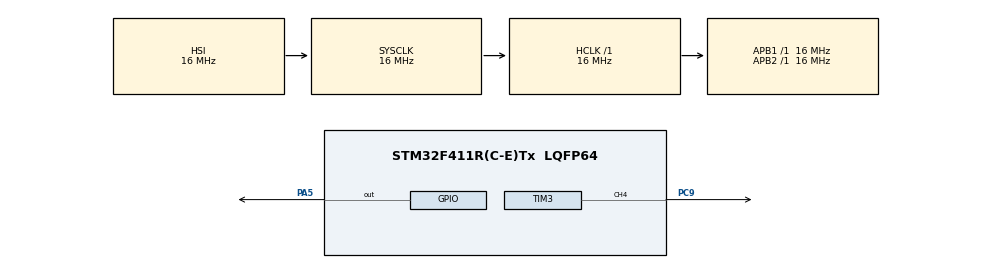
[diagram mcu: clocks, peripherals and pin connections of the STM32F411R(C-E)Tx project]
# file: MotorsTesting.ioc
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Mcu.Family=STM32F4
Mcu.Name=STM32F411R(C-E)Tx
Mcu.Package=LQFP64
NVIC.PriorityGroup=NVIC_PRIORITYGROUP_4
PA5.Signal=GPIO_Output
PC9.Signal=S_TIM3_CH4
ProjectManager.HeapSize=0x200
ProjectManager.StackSize=0x400
ProjectManager.TargetToolchain=STM32CubeIDE
RCC.AHBFreq_Value=16000000
RCC.APB1Freq_Value=16000000
RCC.APB2Freq_Value=16000000
RCC.CortexFreq_Value=16000000
RCC.HSE_VALUE=25000000
RCC.HSI_VALUE=16000000
RCC.LSE_VALUE=32768
RCC.SYSCLKFreq_VALUE=16000000
RCC.VCOOutputFreq_Value=192000000
SH.S_TIM3_CH4.0=TIM3_CH4,PWM Generation4 CH4
TIM3.Channel-PWM\ Generation4\ CH4=TIM_CHANNEL_4
TIM3.Period=15999
TIM3.Prescaler=999
TIM3.Pulse-PWM\ Generation4\ CH4=32000
board=custom

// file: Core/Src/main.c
/* USER CODE BEGIN Header */
/* USER CODE END Header */
#include "main.h"

TIM_HandleTypeDef htim3;

void SystemClock_Config(void);
static void MX_GPIO_Init(void);
static void MX_TIM3_Init(void);
/* USER CODE BEGIN PFP */

static void motorRamp(void);
/* USER CODE END PFP */

int main(void)
{

  /* MCU Configuration--------------------------------------------------------*/

  /* Reset of all peripherals, Initializes the Flash interface and the Systick. */
  HAL_Init();

  /* Configure the system clock */
  SystemClock_Config();

  /* Initialize all configured peripherals */
  MX_GPIO_Init();
  MX_TIM3_Init();
  /* USER CODE BEGIN 2 */
	HAL_TIM_Base_Start(&htim3);
	HAL_TIM_PWM_Start(&htim3,TIM_CHANNEL_4); //Start Pwm signal on PB-6 Pin
/* USER CODE END 2 */

	int pwm=0;
while (1)
	{

	for (pwm=0;pwm<=3906;pwm=pwm+1)  //darkest to brightest: 0-100% duty cycle
		{
		__HAL_TIM_SetCompare(&htim3, TIM_CHANNEL_4, pwm); //update pwm value
		HAL_Delay(5);           //Wait for 5ms
		}
	HAL_Delay(500);  //hold for 0.5s

	for (pwm=3906;pwm>=0;pwm=pwm-1)  //brightest to darkest: 100-0% duty cycle
		{
		__HAL_TIM_SetCompare(&htim3, TIM_CHANNEL_4, pwm);
		HAL_Delay(5);           //Wait for 5ms
		}
	HAL_Delay(500);   //hold for 0.5s

	}
}

void SystemClock_Config(void)
{
  RCC_OscInitTypeDef RCC_OscInitStruct = {0};
  RCC_ClkInitTypeDef RCC_ClkInitStruct = {0};

  /** Configure the main internal regulator output voltage
  */
  __HAL_RCC_PWR_CLK_ENABLE();
  __HAL_PWR_VOLTAGESCALING_CONFIG(PWR_REGULATOR_VOLTAGE_SCALE1);
  /** Initializes the RCC Oscillators according to the specified parameters
  * in the RCC_OscInitTypeDef structure.
  */
  RCC_OscInitStruct.OscillatorType = RCC_OSCILLATORTYPE_HSI;
  RCC_OscInitStruct.HSIState = RCC_HSI_ON;
  RCC_OscInitStruct.HSICalibrationValue = RCC_HSICALIBRATION_DEFAULT;
  RCC_OscInitStruct.PLL.PLLState = RCC_PLL_NONE;
  if (HAL_RCC_OscConfig(&RCC_OscInitStruct) != HAL_OK)
  {
    Error_Handler();
  }
  /** Initializes the CPU, AHB and APB buses clocks
  */
  RCC_ClkInitStruct.ClockType = RCC_CLOCKTYPE_HCLK|RCC_CLOCKTYPE_SYSCLK
                              |RCC_CLOCKTYPE_PCLK1|RCC_CLOCKTYPE_PCLK2;
  RCC_ClkInitStruct.SYSCLKSource = RCC_SYSCLKSOURCE_HSI;
  RCC_ClkInitStruct.AHBCLKDivider = RCC_SYSCLK_DIV1;
  RCC_ClkInitStruct.APB1CLKDivider = RCC_HCLK_DIV1;
  RCC_ClkInitStruct.APB2CLKDivider = RCC_HCLK_DIV1;

  if (HAL_RCC_ClockConfig(&RCC_ClkInitStruct, FLASH_LATENCY_0) != HAL_OK)
  {
    Error_Handler();
  }
}

static void MX_TIM3_Init(void)
{

  TIM_MasterConfigTypeDef sMasterConfig = {0};
  TIM_OC_InitTypeDef sConfigOC = {0};

  htim3.Instance = TIM3;
  htim3.Init.Prescaler = 15;
  htim3.Init.CounterMode = TIM_COUNTERMODE_UP;
  htim3.Init.Period = 3906;
  htim3.Init.ClockDivision = TIM_CLOCKDIVISION_DIV1;
  htim3.Init.AutoReloadPreload = TIM_AUTORELOAD_PRELOAD_DISABLE;
  if (HAL_TIM_PWM_Init(&htim3) != HAL_OK)
  {
    Error_Handler();
  }
  sMasterConfig.MasterOutputTrigger = TIM_TRGO_RESET;
  sMasterConfig.MasterSlaveMode = TIM_MASTERSLAVEMODE_DISABLE;
  if (HAL_TIMEx_MasterConfigSynchronization(&htim3, &sMasterConfig) != HAL_OK)
  {
    Error_Handler();
  }
  sConfigOC.OCMode = TIM_OCMODE_PWM1;
  sConfigOC.Pulse = 1953;
  sConfigOC.OCPolarity = TIM_OCPOLARITY_HIGH;
  sConfigOC.OCFastMode = TIM_OCFAST_DISABLE;
  if (HAL_TIM_PWM_ConfigChannel(&htim3, &sConfigOC, TIM_CHANNEL_4) != HAL_OK)
  {
    Error_Handler();
  }
  HAL_TIM_MspPostInit(&htim3);

}

static void MX_GPIO_Init(void)
{
  GPIO_InitTypeDef GPIO_InitStruct = {0};

  /* GPIO Ports Clock Enable */
  __HAL_RCC_GPIOA_CLK_ENABLE();
  __HAL_RCC_GPIOC_CLK_ENABLE();

  /*Configure GPIO pin Output Level */
  HAL_GPIO_WritePin(GPIOA, GPIO_PIN_5, GPIO_PIN_RESET);

  /*Configure GPIO pin : PA5 */
  GPIO_InitStruct.Pin = GPIO_PIN_5;
  GPIO_InitStruct.Mode = GPIO_MODE_OUTPUT_PP;
  GPIO_InitStruct.Pull = GPIO_NOPULL;
  GPIO_InitStruct.Speed = GPIO_SPEED_FREQ_LOW;
  HAL_GPIO_Init(GPIOA, &GPIO_InitStruct);

}

/* USER CODE BEGIN 4 */

static void motorRamp(void){
	int8_t speedPercent = 0;
	HAL_GPIO_WritePin(GPIOB, GPIO_PIN_1, SET);
	HAL_GPIO_WritePin(GPIOB, GPIO_PIN_15, RESET);

	while(speedPercent!=100){

		speedPercent++;
		//__HAL_TIM_SetCompare(&htim4, TIM_CHANNEL_3, speedPercent);
		HAL_Delay(100); // MS

	}

}

/* USER CODE END 4 */

void Error_Handler(void)
{
}

/************************ (C) COPYRIGHT STMicroelectronics *****END OF FILE****/
